# MK60DZ10 register map
Vendor: Freescale Semiconductor, Inc.; Series: Kinetis_K; File version: 1.6
CPU: CM4 r0p1, little endian, no MPU, no FPU, VTOR, 4 interrupt priority bits
Registers are 32-bit, read-write, reset 0x0 unless marked. A register's access mark holds for its fields unless they carry their own. Offsets are from the block's base; [hi:lo] are bit positions.

## MCG — Multipurpose Clock Generator module
Base 0x40064000; register names take the prefix MCG_
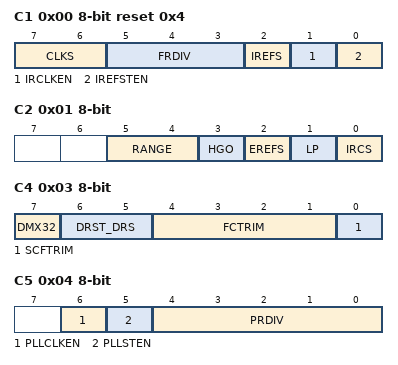
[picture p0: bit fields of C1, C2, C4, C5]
0x00 C1 8-bit reset 0x4 — MCG Control 1 Register
  [7:6] CLKS — Clock Source Select
    0=Encoding 0 - Output of FLL or PLL is selected (depends on PLLS control bit); 1=Encoding 1 - Internal reference clock is selected; 2=Encoding 2 - External reference clock is selected; 3=Encoding 3 - Reserved, defaults to 00
  [5:3] FRDIV — FLL External Reference Divider
    0=If RANGE = 0 , Divide Factor is 1; for all other RANGE values, Divide Factor is 32; 1=If RANGE = 0 , Divide Factor is 2; for all other RANGE values, Divide Factor is 64; 2=If RANGE = 0 , Divide Factor is 4; for all other RANGE values, Divide Factor is 128; 3=If RANGE = 0 , Divide Factor is 8; for all other RANGE values, Divide Factor is 256; 4=If RANGE = 0 , Divide Factor is 16; for all other RANGE values, Divide Factor is 512; 5=If RANGE = 0 , Divide Factor is 32; for all other RANGE values, Divide Factor is 1024; 6=If RANGE = 0 , Divide Factor is 64; for all other RANGE values, Divide Factor is Reserved ; 7=If RANGE = 0 , Divide Factor is 128; for all other RANGE values, Divide Factor is Reserved 
  [2] IREFS — Internal Reference Select
    0=External reference clock is selected; 1=The slow internal reference clock is selected
  [1] IRCLKEN — Internal Reference Clock Enable
    0=MCGIRCLK inactive; 1=MCGIRCLK active
  [0] IREFSTEN — Internal Reference Stop Enable
    0=Internal reference clock is disabled in Stop mode; 1=Internal reference clock is enabled in Stop mode if IRCLKEN is set or if MCG is in FEI, FBI, or BLPI modes before entering Stop mode
0x01 C2 8-bit — MCG Control 2 Register
  [5:4] RANGE — Frequency Range Select
    0=Encoding 0 - Low frequency range selected for the crystal oscillator ; 1=Encoding 1 - High frequency range selected for the crystal oscillator 
  [3] HGO — High Gain Oscillator Select
    0=Configure crystal oscillator for low-power operation; 1=Configure crystal oscillator for high-gain operation
  [2] EREFS — External Reference Select
    0=External reference clock requested; 1=Oscillator requested
  [1] LP — Low Power Select
    0=FLL (or PLL) is not disabled in bypass modes; 1=FLL (or PLL) is disabled in bypass modes (lower power)
  [0] IRCS — Internal Reference Clock Select
    0=Slow internal reference clock selected; 1=Fast internal reference clock selected
0x02 C3 8-bit reset not defined — MCG Control 3 Register
  [7:0] SCTRIM — Slow Internal Reference Clock Trim Setting
0x03 C4 8-bit (reset mask 0xE0) — MCG Control 4 Register
  [7] DMX32 — DCO Maximum Frequency with 32.768 kHz Reference
    0=DCO has a default range of 25%; 1=DCO is fine-tuned for maximum frequency with 32.768 kHz reference
  [6:5] DRST_DRS — DCO Range Select
    0=Encoding 0 - Low range (reset default); 1=Encoding 1 - Mid range; 2=Encoding 2 - Mid-high range; 3=Encoding 3 - High range
  [4:1] FCTRIM — Fast Internal Reference Clock Trim Setting
  [0] SCFTRIM — Slow Internal Reference Clock Fine Trim
0x04 C5 8-bit — MCG Control 5 Register
  [6] PLLCLKEN — PLL Clock Enable
    0=MCGPLLCLK is inactive; 1=MCGPLLCLK is active
  [5] PLLSTEN — PLL Stop Enable
    0=MCGPLLCLK is disabled in any of the Stop modes; 1=MCGPLLCLK is enabled if system is in Normal Stop mode
  [4:0] PRDIV — PLL External Reference Divider
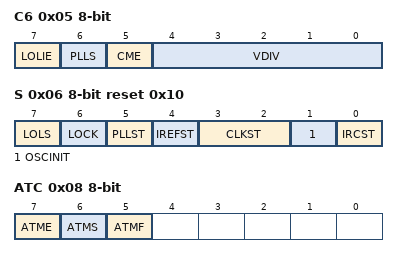
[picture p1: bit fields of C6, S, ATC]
0x05 C6 8-bit — MCG Control 6 Register
  [7] LOLIE — Loss of Lock Interrrupt Enable
    0=No interrupt request is generated on loss of lock; 1=Generate an interrupt request on loss of lock
  [6] PLLS — PLL Select
    0=FLL is selected; 1=PLL is selected (PRDIV need to be programmed to the correct divider to generate a PLL reference clock in the range of 2 - 4 MHz prior to setting the PLLS bit)
  [5] CME — Clock Monitor Enable
    0=External clock monitor is disabled; 1=Generate a reset request on loss of external clock
  [4:0] VDIV — VCO Divider
0x06 S 8-bit reset 0x10 — MCG Status Register
  [7] LOLS — Loss of Lock Status
    0=PLL has not lost lock since LOLS was last cleared; 1=PLL has lost lock since LOLS was last cleared
  [6] LOCK ro — Lock Status
    0=PLL is currently unlocked; 1=PLL is currently locked
  [5] PLLST ro — PLL Select Status
    0=Source of PLLS clock is FLL clock; 1=Source of PLLS clock is PLL clock
  [4] IREFST ro — Internal Reference Status
    0=Source of FLL reference clock is the external reference clock; 1=Source of FLL reference clock is the internal reference clock
  [3:2] CLKST ro — Clock Mode Status
    0=Encoding 0 - Output of the FLL is selected (reset default); 1=Encoding 1 - Internal reference clock is selected; 2=Encoding 2 - External reference clock is selected; 3=Encoding 3 - Output of the PLL is selected
  [1] OSCINIT ro — OSC Initialization
  [0] IRCST ro — Internal Reference Clock Status
    0=Source of internal reference clock is the slow clock (32 kHz IRC); 1=Source of internal reference clock is the fast clock (2 MHz IRC)
0x08 ATC 8-bit — MCG Auto Trim Control Register
  [7] ATME — Automatic Trim Machine Enable
    0=Auto Trim Machine disabled; 1=Auto Trim Machine enabled
  [6] ATMS — Automatic Trim Machine Select
    0=32 kHz Internal Reference Clock selected; 1=4 MHz Internal Reference Clock selected
  [5] ATMF ro — Automatic Trim machine Fail Flag
    0=Automatic Trim Machine completed normally; 1=Automatic Trim Machine failed
0x0A ATCVH 8-bit — MCG Auto Trim Compare Value High Register
  [7:0] ATCVH — ATM Compare Value High
0x0B ATCVL 8-bit — MCG Auto Trim Compare Value Low Register
  [7:0] ATCVL — ATM Compare Value Low

## Notices in the file
Redistribution and use in source and binary forms, with or without modification,
are permitted provided that the following conditions are met:
o Redistributions of source code must retain the above copyright notice, this list
of conditions and the following disclaimer.
o Redistributions in binary form must reproduce the above copyright notice, this
list of conditions and the following disclaimer in the documentation and/or
other materials provided with the distribution.
o Neither the name of Freescale Semiconductor, Inc. nor the names of its
contributors may be used to endorse or promote products derived from this
software without specific prior written permission.
THIS SOFTWARE IS PROVIDED BY THE COPYRIGHT HOLDERS AND CONTRIBUTORS "AS IS" AND
ANY EXPRESS OR IMPLIED WARRANTIES, INCLUDING, BUT NOT LIMITED TO, THE IMPLIED
WARRANTIES OF MERCHANTABILITY AND FITNESS FOR A PARTICULAR PURPOSE ARE
DISCLAIMED. IN NO EVENT SHALL THE COPYRIGHT HOLDER OR CONTRIBUTORS BE LIABLE FOR
ANY DIRECT, INDIRECT, INCIDENTAL, SPECIAL, EXEMPLARY, OR CONSEQUENTIAL DAMAGES
(INCLUDING, BUT NOT LIMITED TO, PROCUREMENT OF SUBSTITUTE GOODS OR SERVICES;
LOSS OF USE, DATA, OR PROFITS; OR BUSINESS INTERRUPTION) HOWEVER CAUSED AND ON
ANY THEORY OF LIABILITY, WHETHER IN CONTRACT, STRICT LIABILITY, OR TORT
(INCLUDING NEGLIGENCE OR OTHERWISE) ARISING IN ANY WAY OUT OF THE USE OF THIS
SOFTWARE, EVEN IF ADVISED OF THE POSSIBILITY OF SUCH DAMAGE.
